AUTOSAR XML (schema 00046)
package /ComponentTypes
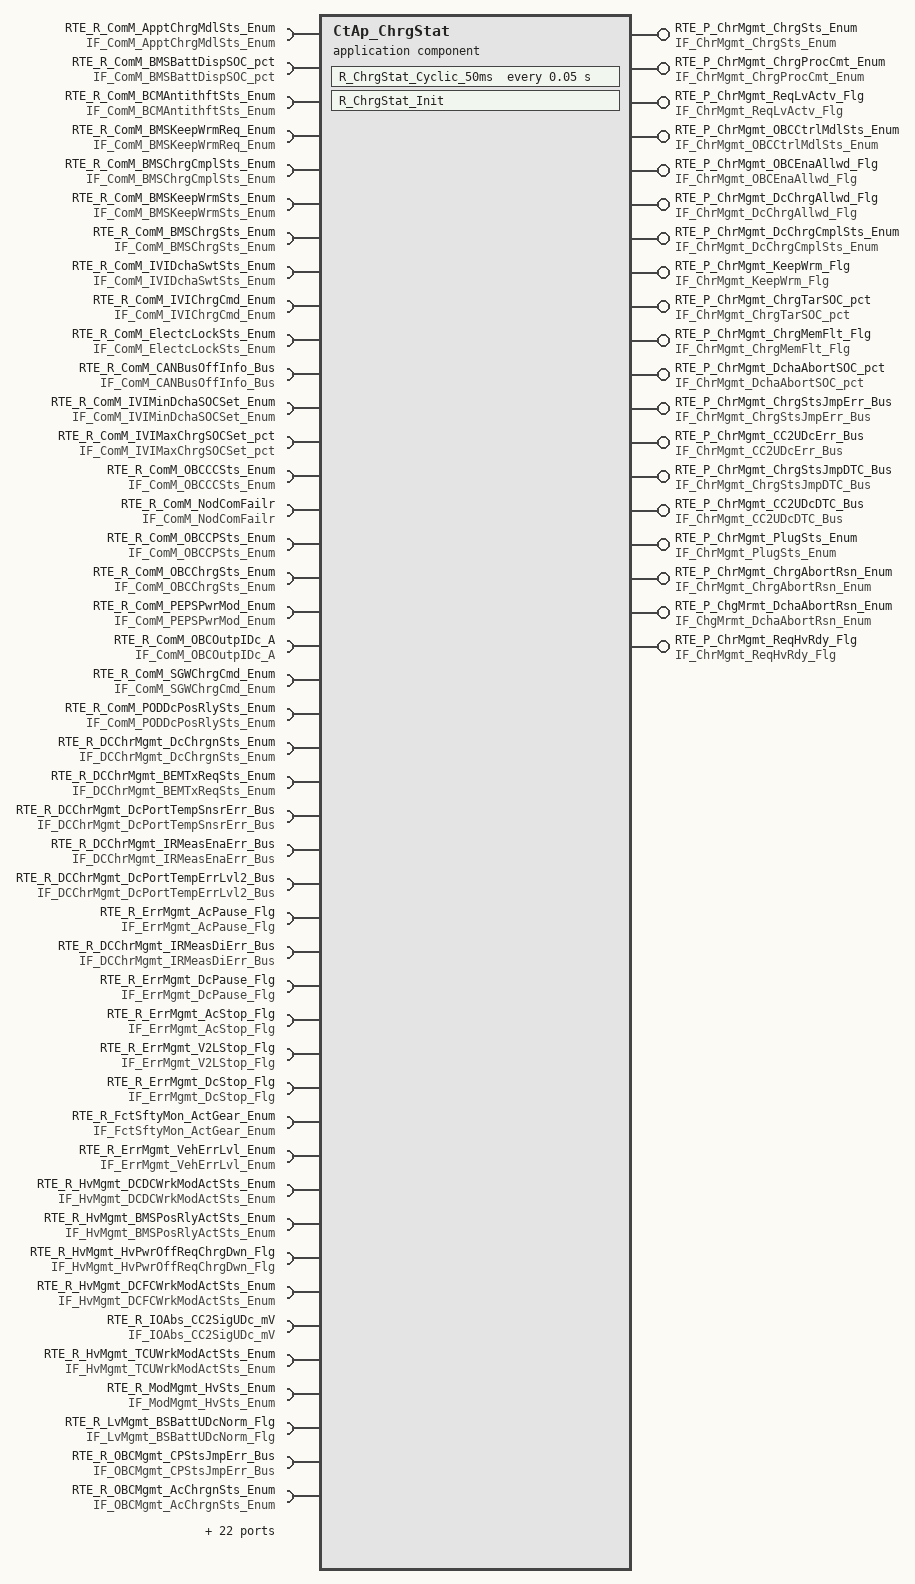
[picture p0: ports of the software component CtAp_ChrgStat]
  application sw component type CtAp_ChrgStat
    18 x provide port:
      RTE_P_ChrMgmt_ChrgSts_Enum: nonqueued-sender-com-spec{data-element=tec_ChrMgmt_ChrgSts_Enum, init-value=0}, provided-interface=IF_ChrMgmt_ChrgSts_Enum
      RTE_P_ChrMgmt_ChrgProcCmt_Enum: nonqueued-sender-com-spec{data-element=tec_ChrMgmt_ChrgProcCmt_Enum, init-value=0}, provided-interface=IF_ChrMgmt_ChrgProcCmt_Enum
      RTE_P_ChrMgmt_ReqLvActv_Flg: nonqueued-sender-com-spec{data-element=tec_ChrMgmt_ReqLvActv_Flg, init-value=0}, provided-interface=IF_ChrMgmt_ReqLvActv_Flg
      RTE_P_ChrMgmt_OBCCtrlMdlSts_Enum: nonqueued-sender-com-spec{data-element=tec_ChrMgmt_OBCCtrlMdlSts_Enum, init-value=0}, provided-interface=IF_ChrMgmt_OBCCtrlMdlSts_Enum
      RTE_P_ChrMgmt_OBCEnaAllwd_Flg: nonqueued-sender-com-spec{data-element=tec_ChrMgmt_OBCEnaAllwd_Flg, init-value=0}, provided-interface=IF_ChrMgmt_OBCEnaAllwd_Flg
      RTE_P_ChrMgmt_DcChrgAllwd_Flg: nonqueued-sender-com-spec{data-element=tec_ChrMgmt_DcChrgAllwd_Flg, init-value=0}, provided-interface=IF_ChrMgmt_DcChrgAllwd_Flg
      RTE_P_ChrMgmt_DcChrgCmplSts_Enum: nonqueued-sender-com-spec{data-element=tec_ChrMgmt_DcChrgCmplSts_Enum, init-value=0}, provided-interface=IF_ChrMgmt_DcChrgCmplSts_Enum
      RTE_P_ChrMgmt_KeepWrm_Flg: nonqueued-sender-com-spec{data-element=tec_ChrMgmt_KeepWrm_Flg, init-value=0}, provided-interface=IF_ChrMgmt_KeepWrm_Flg
      RTE_P_ChrMgmt_ChrgTarSOC_pct: nonqueued-sender-com-spec{data-element=tec_ChrMgmt_ChrgTarSOC_pct, init-value=0}, provided-interface=IF_ChrMgmt_ChrgTarSOC_pct
      RTE_P_ChrMgmt_ChrgMemFlt_Flg: nonqueued-sender-com-spec{data-element=tec_ChrMgmt_ChrgMemFlt_Flg, init-value=0}, provided-interface=IF_ChrMgmt_ChrgMemFlt_Flg
      RTE_P_ChrMgmt_DchaAbortSOC_pct: nonqueued-sender-com-spec{data-element=tec_ChrMgmt_DchaAbortSOC_pct, init-value=0}, provided-interface=IF_ChrMgmt_DchaAbortSOC_pct
      RTE_P_ChrMgmt_ChrgStsJmpErr_Bus: nonqueued-sender-com-spec{data-element=tec_ChrMgmt_ChrgStsJmpErr_Bus, init-value=fields=[ChrMgmt_MonStatChrgStsJmpErr:0, ChrMgmt_MonResChrgStsJmpErr:0, ChrMgmt_ErrStatChrgStsJmpErr:0, ChrMgmt_ErrResChrgStsJmpErr:0]}, provided-interface=IF_ChrMgmt_ChrgStsJmpErr_Bus
      RTE_P_ChrMgmt_CC2UDcErr_Bus: nonqueued-sender-com-spec{data-element=tec_ChrMgmt_CC2UDcErr_Bus, init-value=fields=[ChrMgmt_MonStatCC2UDcErr:0, ChrMgmt_MonResCC2UDcErr:0, ChrMgmt_ErrStatCC2UDcErr:0, ChrMgmt_ErrResCC2UDcErr:0]}, provided-interface=IF_ChrMgmt_CC2UDcErr_Bus
      RTE_P_ChrMgmt_ChrgStsJmpDTC_Bus: nonqueued-sender-com-spec{data-element=tec_ChrMgmt_ChrgStsJmpErrDTC_Bus, init-value=fields=[ChrMgmt_MonStatChrgStsJmpErrDTC:0, ChrMgmt_MonResChrgStsJmpErrDTC:0, ChrMgmt_ErrStatChrgStsJmpErrDTC:0, ChrMgmt_ErrResChrgStsJmpErrDTC:0]}, provided-interface=IF_ChrMgmt_ChrgStsJmpDTC_Bus
      RTE_P_ChrMgmt_CC2UDcDTC_Bus: nonqueued-sender-com-spec{data-element=tec_ChrMgmt_CC2UDcErrDTC_Bus, init-value=fields=[ChrMgmt_MonStatCC2UDcErrDTC:0, ChrMgmt_MonResCC2UDcErrDTC:0, ChrMgmt_ErrStatCC2UDcErrDTC:0, ChrMgmt_ErrResCC2UDcErrDTC:0]}, provided-interface=IF_ChrMgmt_CC2UDcDTC_Bus
      RTE_P_ChrMgmt_PlugSts_Enum: nonqueued-sender-com-spec{data-element=tec_ChrMgmt_PlugSts_Enum, init-value=0}, provided-interface=IF_ChrMgmt_PlugSts_Enum
      RTE_P_ChrMgmt_ChrgAbortRsn_Enum: nonqueued-sender-com-spec{data-element=tec_ChrMgmt_ChrgAbortRsn_Enum, init-value=0}, provided-interface=IF_ChrMgmt_ChrgAbortRsn_Enum
      RTE_P_ChgMrmt_DchaAbortRsn_Enum: nonqueued-sender-com-spec{data-element=tec_ChrMgmt_DchaAbortRsn_Enum, init-value=0}, provided-interface=IF_ChgMrmt_DchaAbortRsn_Enum
    57 x require port:
      RTE_R_ComM_ApptChrgMdlSts_Enum: nonqueued-receiver-com-spec{data-element=tec_ComM_ApptChrgMdlSts_Enum, filter=data-filter-type=ALWAYS, init-value=0}, required-interface=IF_ComM_ApptChrgMdlSts_Enum
      RTE_R_ComM_BMSBattDispSOC_pct: nonqueued-receiver-com-spec{data-element=tec_ComM_BMSBattDispSOC_pct, filter=data-filter-type=ALWAYS, init-value=0}, required-interface=IF_ComM_BMSBattDispSOC_pct
      RTE_R_ComM_BCMAntithftSts_Enum: nonqueued-receiver-com-spec{data-element=tec_ComM_BCMAntithftSts_Enum, filter=data-filter-type=ALWAYS, init-value=0}, required-interface=IF_ComM_BCMAntithftSts_Enum
      RTE_R_ComM_BMSKeepWrmReq_Enum: nonqueued-receiver-com-spec{data-element=tec_ComM_BMSKeepWrmReq_Enum, filter=data-filter-type=ALWAYS, init-value=0}, required-interface=IF_ComM_BMSKeepWrmReq_Enum
      RTE_R_ComM_BMSChrgCmplSts_Enum: nonqueued-receiver-com-spec{data-element=tec_ComM_BMSChrgCmplSts_Enum, filter=data-filter-type=ALWAYS, init-value=0}, required-interface=IF_ComM_BMSChrgCmplSts_Enum
      RTE_R_ComM_BMSKeepWrmSts_Enum: nonqueued-receiver-com-spec{data-element=tec_ComM_BMSKeepWrmSts_Enum, filter=data-filter-type=ALWAYS, init-value=0}, required-interface=IF_ComM_BMSKeepWrmSts_Enum
      RTE_R_ComM_BMSChrgSts_Enum: nonqueued-receiver-com-spec{data-element=tec_ComM_BMSChrgSts_Enum, filter=data-filter-type=ALWAYS, init-value=0}, required-interface=IF_ComM_BMSChrgSts_Enum
      RTE_R_ComM_IVIDchaSwtSts_Enum: nonqueued-receiver-com-spec{data-element=tec_ComM_IVIDchaSwtSts_Enum, filter=data-filter-type=ALWAYS, init-value=0}, required-interface=IF_ComM_IVIDchaSwtSts_Enum
      RTE_R_ComM_IVIChrgCmd_Enum: nonqueued-receiver-com-spec{data-element=tec_ComM_IVIChrgCmd_Enum, filter=data-filter-type=ALWAYS, init-value=0}, required-interface=IF_ComM_IVIChrgCmd_Enum
      RTE_R_ComM_ElectcLockSts_Enum: nonqueued-receiver-com-spec{data-element=tec_ComM_ElectcLockSts_Enum, filter=data-filter-type=ALWAYS, init-value=0}, required-interface=IF_ComM_ElectcLockSts_Enum
      RTE_R_ComM_CANBusOffInfo_Bus: required-interface=IF_ComM_CANBusOffInfo_Bus
        required-com-specs:
          data-element=tec_ComM_EPTCANBusOffInfo_Bus, filter=data-filter-type=ALWAYS, init-value=fields=[ComM_MonStatEPTCANBusOffInfo:0, ComM_MonResEPTCANBusOffInfo:0, ComM_ErrStatEPTCANBusOffInfo:0, ComM_ErrResEPTCANBusOffInfo:0]
          data-element=tec_ComM_CHCANBusOffInfo_Bus, filter=data-filter-type=ALWAYS, init-value=fields=[ComM_MonStatCHCANBusOffInfo:0, ComM_MonResCHCANBusOffInfo:0, ComM_ErrStatCHCANBusOffInfo:0, ComM_ErrResCHCANBusOffInfo:0]
          data-element=tec_ComM_EPTCANBusOffDTCInfo_Bus, filter=data-filter-type=ALWAYS, init-value=fields=[ComM_MonStatEPTCANBusOffDTCInfo:0, ComM_MonResEPTCANBusOffDTCInfo:0, ComM_ErrStatEPTCANBusOffDTCInfo:0, ComM_ErrResEPTCANBusOffDTCInfo:0]
          data-element=tec_ComM_CHCANBusOffDTCInfo_Bus, filter=data-filter-type=ALWAYS, init-value=fields=[ComM_MonStatCHCANBusOffDTCInfo:0, ComM_MonResCHCANBusOffDTCInfo:0, ComM_ErrStatCHCANBusOffDTCInfo:0, ComM_ErrResCHCANBusOffDTCInfo:0]
          data-element=tec_ComM_DCCANBusOffDTCInfo_Bus, init-value=fields=[ComM_MonStatDCCANDTCBusOffInfo:0, ComM_MonResDCCANDTCBusOffInfo:0, ComM_ErrStatDCCANDTCBusOffInfo:0, ComM_ErrResDCCANDTCBusOffInfo:0]
          data-element=tec_ComM_DCCANBusOffInfo_Bus, init-value=fields=[ComM_MonStatDCCANBusOffInfo:0, ComM_MonResDCCANBusOffInfo:0, ComM_ErrStatDCCANBusOffInfo:0, ComM_ErrResDCCANBusOffInfo:0]
      RTE_R_ComM_IVIMinDchaSOCSet_Enum: nonqueued-receiver-com-spec{data-element=tec_ComM_IVIMinDchaSOCSet_Enum, filter=data-filter-type=ALWAYS, init-value=0}, required-interface=IF_ComM_IVIMinDchaSOCSet_Enum
      RTE_R_ComM_IVIMaxChrgSOCSet_pct: nonqueued-receiver-com-spec{data-element=tec_ComM_IVIMaxChrgSOCSet_pct, filter=data-filter-type=ALWAYS, init-value=0}, required-interface=IF_ComM_IVIMaxChrgSOCSet_pct
      RTE_R_ComM_OBCCCSts_Enum: nonqueued-receiver-com-spec{data-element=tec_ComM_OBCCCSts_Enum, filter=data-filter-type=ALWAYS, init-value=0}, required-interface=IF_ComM_OBCCCSts_Enum
      RTE_R_ComM_NodComFailr: required-interface=IF_ComM_NodComFailr
        required-com-specs:
          data-element=tec_ComM_ACUNodComFailr_Flg, filter=data-filter-type=ALWAYS, init-value=0
          data-element=tec_ComM_SGWNodComFailr_Flg, filter=data-filter-type=ALWAYS, init-value=0
          data-element=tec_ComM_CGWNodComFailr_Flg, filter=data-filter-type=ALWAYS, init-value=0
          data-element=tec_ComM_TCUNodComFailr_Flg, filter=data-filter-type=ALWAYS, init-value=0
          data-element=tec_ComM_BCMNodComFailr_Flg, filter=data-filter-type=ALWAYS, init-value=0
          data-element=tec_ComM_PRNDNodComFailr_Flg, filter=data-filter-type=ALWAYS, init-value=0
          data-element=tec_ComM_IVINodComFailr_Flg, filter=data-filter-type=ALWAYS, init-value=0
          data-element=tec_ComM_DCDCNodComFailr_Flg, filter=data-filter-type=ALWAYS, init-value=0
          data-element=tec_ComM_OBCNodComFailr_Flg, filter=data-filter-type=ALWAYS, init-value=0
          data-element=tec_ComM_CHIBSNodComFailr_Flg, filter=data-filter-type=ALWAYS, init-value=0
          data-element=tec_ComM_MCUNodComFailr_Flg, filter=data-filter-type=ALWAYS, init-value=0
          data-element=tec_ComM_EVCOMNodComFailr_Flg, filter=data-filter-type=ALWAYS, init-value=0
          data-element=tec_ComM_EPTIBSNodComFailr_Flg, filter=data-filter-type=ALWAYS, init-value=0
          data-element=tec_ComM_DCMNodComFailr_Flg, filter=data-filter-type=ALWAYS, init-value=0
          data-element=tec_ComM_BMSNodComFailr_Flg, filter=data-filter-type=ALWAYS, init-value=0
          data-element=tec_ComM_APTCNodComFailr_Flg, filter=data-filter-type=ALWAYS, init-value=0
          data-element=tec_ComM_ADCUNodComFailr_Flg, filter=data-filter-type=ALWAYS, init-value=0
          data-element=tec_ComM_DCMRRNodComFailr_Flg, filter=data-filter-type=ALWAYS, init-value=0
          data-element=tec_ComM_DCMRLNodComFailr_Flg, filter=data-filter-type=ALWAYS, init-value=0
          data-element=tec_ComM_DCMFRNodComFailr_Flg, filter=data-filter-type=ALWAYS, init-value=0
          data-element=tec_ComM_DCMFLNodComFailr_Flg, filter=data-filter-type=ALWAYS, init-value=0
          data-element=tec_ComM_SGWCHNodComFailr_Flg, init-value=0
      RTE_R_ComM_OBCCPSts_Enum: nonqueued-receiver-com-spec{data-element=tec_ComM_OBCCPSts_Enum, filter=data-filter-type=ALWAYS, init-value=0}, required-interface=IF_ComM_OBCCPSts_Enum
      RTE_R_ComM_OBCChrgSts_Enum: nonqueued-receiver-com-spec{data-element=tec_ComM_OBCChrgSts_Enum, filter=data-filter-type=ALWAYS, init-value=0}, required-interface=IF_ComM_OBCChrgSts_Enum
      RTE_R_ComM_PEPSPwrMod_Enum: nonqueued-receiver-com-spec{data-element=tec_ComM_PEPSPwrMod_Enum, filter=data-filter-type=ALWAYS, init-value=0}, required-interface=IF_ComM_PEPSPwrMod_Enum
      RTE_R_ComM_OBCOutpIDc_A: nonqueued-receiver-com-spec{data-element=tec_ComM_OBCOutpIDc_A, filter=data-filter-type=ALWAYS, init-value=0}, required-interface=IF_ComM_OBCOutpIDc_A
      RTE_R_ComM_SGWChrgCmd_Enum: nonqueued-receiver-com-spec{data-element=tec_ComM_SGWChrgCmd_Enum, filter=data-filter-type=ALWAYS, init-value=0}, required-interface=IF_ComM_SGWChrgCmd_Enum
      RTE_R_ComM_PODDcPosRlySts_Enum: nonqueued-receiver-com-spec{data-element=tec_ComM_PODDcPosRlySts_Enum, filter=data-filter-type=ALWAYS, init-value=0}, required-interface=IF_ComM_PODDcPosRlySts_Enum
      RTE_R_DCChrMgmt_DcChrgnSts_Enum: nonqueued-receiver-com-spec{data-element=tec_DCChrMgmt_DcChrgnSts_Enum, filter=data-filter-type=ALWAYS, init-value=0}, required-interface=IF_DCChrMgmt_DcChrgnSts_Enum
      RTE_R_DCChrMgmt_BEMTxReqSts_Enum: nonqueued-receiver-com-spec{data-element=tec_DCChrMgmt_BEMTxReqSts_Enum, filter=data-filter-type=ALWAYS, init-value=0}, required-interface=IF_DCChrMgmt_BEMTxReqSts_Enum
      RTE_R_DCChrMgmt_DcPortTempSnsrErr_Bus: nonqueued-receiver-com-spec{data-element=tec_DCChrMgmt_DcPortTempSnsrErr_Bus, filter=data-filter-type=ALWAYS, init-value=fields=[DCChrMgmt_MonStatDcPortTempSnsrErr:0, DCChrMgmt_MonResDcPortTempSnsrErr:0, DCChrMgmt_ErrStatDcPortTempSnsrErr:0, DCChrMgmt_ErrResDcPortTempSnsrErr:0]}, required-interface=IF_DCChrMgmt_DcPortTempSnsrErr_Bus
      RTE_R_DCChrMgmt_IRMeasEnaErr_Bus: nonqueued-receiver-com-spec{data-element=tec_DCChrMgmt_IRMeasEnaErr_Bus, filter=data-filter-type=ALWAYS, init-value=fields=[DCChrMgmt_MonStatIRMeasEnaErr:0, DCChrMgmt_MonResIRMeasEnaErr:0, DCChrMgmt_ErrStatIRMeasEnaErr:0, DCChrMgmt_ErrResIRMeasEnaErr:0]}, required-interface=IF_DCChrMgmt_IRMeasEnaErr_Bus
      RTE_R_DCChrMgmt_DcPortTempErrLvl2_Bus: nonqueued-receiver-com-spec{data-element=tec_DCChrMgmt_DcPortTempErrLvl2_Bus, filter=data-filter-type=ALWAYS, init-value=fields=[DCChrMgmt_MonStatDcPortTempErrLvl2:0, DCChrMgmt_MonResDcPortTempErrLvl2:0, DCChrMgmt_ErrStatDcPortTempErrLvl2:0, DCChrMgmt_ErrResDcPortTempErrLvl2:0]}, required-interface=IF_DCChrMgmt_DcPortTempErrLvl2_Bus
      RTE_R_ErrMgmt_AcPause_Flg: nonqueued-receiver-com-spec{data-element=tec_ErrMgmt_AcPause_Flg, filter=data-filter-type=ALWAYS, init-value=0}, required-interface=IF_ErrMgmt_AcPause_Flg
      RTE_R_DCChrMgmt_IRMeasDiErr_Bus: nonqueued-receiver-com-spec{data-element=tec_DCChrMgmt_IRMeasDiErr_Bus, filter=data-filter-type=ALWAYS, init-value=fields=[DCChrMgmt_MonStatIRMeasDiErr:0, DCChrMgmt_MonResIRMeasDiErr:0, DCChrMgmt_ErrStatIRMeasDiErr:0, DCChrMgmt_ErrResIRMeasDiErr:0]}, required-interface=IF_DCChrMgmt_IRMeasDiErr_Bus
      RTE_R_ErrMgmt_DcPause_Flg: nonqueued-receiver-com-spec{data-element=tec_ErrMgmt_DcPause_Flg, filter=data-filter-type=ALWAYS, init-value=0}, required-interface=IF_ErrMgmt_DcPause_Flg
      RTE_R_ErrMgmt_AcStop_Flg: nonqueued-receiver-com-spec{data-element=tec_ErrMgmt_AcStop_Flg, filter=data-filter-type=ALWAYS, init-value=0}, required-interface=IF_ErrMgmt_AcStop_Flg
      RTE_R_ErrMgmt_V2LStop_Flg: nonqueued-receiver-com-spec{data-element=tec_ErrMgmt_V2LStop_Flg, filter=data-filter-type=ALWAYS, init-value=0}, required-interface=IF_ErrMgmt_V2LStop_Flg
      RTE_R_ErrMgmt_DcStop_Flg: nonqueued-receiver-com-spec{data-element=tec_ErrMgmt_DcStop_Flg, filter=data-filter-type=ALWAYS, init-value=0}, required-interface=IF_ErrMgmt_DcStop_Flg
      RTE_R_FctSftyMon_ActGear_Enum: nonqueued-receiver-com-spec{data-element=tec_FctSftyMon_ActGear_Enum, filter=data-filter-type=ALWAYS, init-value=0}, required-interface=IF_FctSftyMon_ActGear_Enum
      RTE_R_ErrMgmt_VehErrLvl_Enum: nonqueued-receiver-com-spec{data-element=tec_ErrMgmt_VehErrLvl_Enum, filter=data-filter-type=ALWAYS, init-value=0}, required-interface=IF_ErrMgmt_VehErrLvl_Enum
      RTE_R_HvMgmt_DCDCWrkModActSts_Enum: nonqueued-receiver-com-spec{data-element=tec_HvMgmt_DCDCWrkModActSts_Enum, filter=data-filter-type=ALWAYS, init-value=0}, required-interface=IF_HvMgmt_DCDCWrkModActSts_Enum
      RTE_R_HvMgmt_BMSPosRlyActSts_Enum: nonqueued-receiver-com-spec{data-element=tec_HvMgmt_BMSPosRlyActSts_Enum, filter=data-filter-type=ALWAYS, init-value=0}, required-interface=IF_HvMgmt_BMSPosRlyActSts_Enum
      RTE_R_HvMgmt_HvPwrOffReqChrgDwn_Flg: nonqueued-receiver-com-spec{data-element=tec_HvMgmt_HvPwrOffReqChrgDwn_Flg, filter=data-filter-type=ALWAYS, init-value=0}, required-interface=IF_HvMgmt_HvPwrOffReqChrgDwn_Flg
      RTE_R_HvMgmt_DCFCWrkModActSts_Enum: nonqueued-receiver-com-spec{data-element=tec_HvMgmt_DCFCWrkModActSts_Enum, filter=data-filter-type=ALWAYS, init-value=0}, required-interface=IF_HvMgmt_DCFCWrkModActSts_Enum
      RTE_R_IOAbs_CC2SigUDc_mV: nonqueued-receiver-com-spec{data-element=tec_IOAbs_CC2SigUDc_mV, filter=data-filter-type=ALWAYS, init-value=0}, required-interface=IF_IOAbs_CC2SigUDc_mV
      RTE_R_HvMgmt_TCUWrkModActSts_Enum: nonqueued-receiver-com-spec{data-element=tec_HvMgmt_TCUWrkModActSts_Enum, filter=data-filter-type=ALWAYS, init-value=0}, required-interface=IF_HvMgmt_TCUWrkModActSts_Enum
      RTE_R_ModMgmt_HvSts_Enum: nonqueued-receiver-com-spec{data-element=tec_ModMgmt_HvSts_Enum, filter=data-filter-type=ALWAYS, init-value=0}, required-interface=IF_ModMgmt_HvSts_Enum
      RTE_R_LvMgmt_BSBattUDcNorm_Flg: nonqueued-receiver-com-spec{data-element=tec_LvMgmt_BSBattUDcNorm_Flg, filter=data-filter-type=ALWAYS, init-value=0}, required-interface=IF_LvMgmt_BSBattUDcNorm_Flg
      RTE_R_OBCMgmt_CPStsJmpErr_Bus: nonqueued-receiver-com-spec{data-element=tec_OBCMgmt_CPStsJmpErr_Bus, filter=data-filter-type=ALWAYS, init-value=fields=[OBCMgmt_MonStatCPStsJmpErr:0, OBCMgmt_MonResCPStsJmpErr:0, OBCMgmt_ErrStatCPStsJmpErr:0, OBCMgmt_ErrResCPStsJmpErr:0]}, required-interface=IF_OBCMgmt_CPStsJmpErr_Bus
      RTE_R_OBCMgmt_AcChrgnSts_Enum: nonqueued-receiver-com-spec{data-element=tec_OBCMgmt_AcChrgnSts_Enum, filter=data-filter-type=ALWAYS, init-value=0}, required-interface=IF_OBCMgmt_AcChrgnSts_Enum
      RTE_R_OBCMgmt_OBCDchaStsErr_Bus: nonqueued-receiver-com-spec{data-element=tec_OBCMgmt_OBCDchaStsErr_Bus, filter=data-filter-type=ALWAYS, init-value=fields=[OBCMgmt_MonStatOBCDchaStsErr:0, OBCMgmt_MonResOBCDchaStsErr:0, OBCMgmt_ErrStatOBCDchaStsErr:0, OBCMgmt_ErrResOBCDchaStsErr:0]}, required-interface=IF_OBCMgmt_OBCDchaStsErr_Bus
      RTE_R_OBCMgmt_OBCChrgStsErr_Bus: nonqueued-receiver-com-spec{data-element=tec_OBCMgmt_OBCChrgStsErr_Bus, filter=data-filter-type=ALWAYS, init-value=fields=[OBCMgmt_MonStatOBCChrgStsErr:0, OBCMgmt_MonResOBCChrgStsErr:0, OBCMgmt_ErrStatOBCChrgStsErr:0, OBCMgmt_ErrResOBCChrgStsErr:0]}, required-interface=IF_OBCMgmt_OBCChrgStsErr_Bus
      RTE_R_OBCMgmt_OBCInpUDcLoErr_Bus: nonqueued-receiver-com-spec{data-element=tec_OBCMgmt_OBCInpUDcLoErr_Bus, filter=data-filter-type=ALWAYS, init-value=fields=[OBCMgmt_MonStatOBCInpUDcLoErr:0, OBCMgmt_MonResOBCInpUDcLoErr:0, OBCMgmt_ErrStatOBCInpUDcLoErr:0, OBCMgmt_ErrResOBCInpUDcLoErr:0]}, required-interface=IF_OBCMgmt_OBCInpUDcLoErr_Bus
      RTE_R_OBCMgmt_S2SwtClsErr_Bus: nonqueued-receiver-com-spec{data-element=tec_OBCMgmt_S2SwtClsErr_Bus, filter=data-filter-type=ALWAYS, init-value=fields=[OBCMgmt_MonStatS2SwtClsErr:0, OBCMgmt_MonResS2SwtClsErr:0, OBCMgmt_ErrStatS2SwtClsErr:0, OBCMgmt_ErrResS2SwtClsErr:0]}, required-interface=IF_OBCMgmt_S2SwtClsErr_Bus
      RTE_R_VehMot_VehStdl_Flg: nonqueued-receiver-com-spec{data-element=tec_VehMot_VehStdl_Flg, filter=data-filter-type=ALWAYS, init-value=0}, required-interface=IF_VehMot_VehStdl_Flg
      RTE_R_OBCMgmt_OBCDiErr_Bus: nonqueued-receiver-com-spec{data-element=tec_OBCMgmt_OBCDiErr_Bus, filter=data-filter-type=ALWAYS, init-value=fields=[OBCMgmt_MonStatOBCDiErr:0, OBCMgmt_MonResOBCDiErr:0, OBCMgmt_ErrStatOBCDiErr:0, OBCMgmt_ErrResOBCDiErr:0]}, required-interface=IF_OBCMgmt_OBCDiErr_Bus
      RTE_R_OBCMgmt_OBCPreheatStsErr_Bus: nonqueued-receiver-com-spec{data-element=tec_OBCMgmt_OBCPreheatStsErr_Bus, filter=data-filter-type=ALWAYS, init-value=fields=[OBCMgmt_MonStatOBCPreheatStsErr:0, OBCMgmt_MonResOBCPreheatStsErr:0, OBCMgmt_ErrStatOBCPreheatStsErr:0, OBCMgmt_ErrResOBCPreheatStsErr:0]}, required-interface=IF_OBCMgmt_OBCPreheatStsErr_Bus
      RTE_R_ChrMgmt_AcPreheatUDcCtrlErr_Bus: nonqueued-receiver-com-spec{data-element=tec_ChrMgmt_AcPreheatUDcCtrlErr_Bus, filter=data-filter-type=ALWAYS, init-value=fields=[ChrMgmt_MonStatAcPreheatUDcCtrlErr:0, ChrMgmt_MonResAcPreheatUDcCtrlErr:0, ChrMgmt_ErrStatAcPreheatUDcCtrlErr:0, ChrMgmt_ErrResAcPreheatUDcCtrlErr:0]}, required-interface=IF_ChrMgmt_AcPreheatUDcCtrlErr_Bus
      RTE_R_ChrMgmt_DcPreheatUDcCtrlErr_Bus: nonqueued-receiver-com-spec{data-element=tec_ChrMgmt_DcPreheatUDcCtrlErr_Bus, filter=data-filter-type=ALWAYS, init-value=fields=[ChrMgmt_MonStatDcPreheatUDcCtrlErr:0, ChrMgmt_MonResDcPreheatUDcCtrlErr:0, ChrMgmt_ErrStatDcPreheatUDcCtrlErr:0, ChrMgmt_ErrResDcPreheatUDcCtrlErr:0]}, required-interface=IF_ChrMgmt_DcPreheatUDcCtrlErr_Bus
      RTE_R_ChrMgmt_PreheatIRChkErr_Bus: nonqueued-receiver-com-spec{data-element=tec_ChrMgmt_PreheatIRChkErr_Bus, filter=data-filter-type=ALWAYS, init-value=fields=[ChrMgmt_MonStatPreheatIRChkErr:0, ChrMgmt_MonResPreheatIRChkErr:0, ChrMgmt_ErrStatPreheatIRChkErr:0, ChrMgmt_ErrResPreheatIRChkErr:0]}, required-interface=IF_ChrMgmt_PreheatIRChkErr_Bus
      RTE_R_ChrMgmt_KeepWrmTim_min: nonqueued-receiver-com-spec{data-element=tec_ChrMgmt_KeepWrmTim_min, filter=data-filter-type=ALWAYS, init-value=0}, required-interface=IF_ChrMgmt_KeepWrmTim_min
      RTE_R_ChrMgmt_PreheatSts_Enum: nonqueued-receiver-com-spec{data-element=tec_ChrMgmt_PreheatSts_Enum, filter=data-filter-type=ALWAYS, init-value=0}, required-interface=IF_ChrMgmt_PreheatSts_Enum
      RTE_R_ChrMgmt_VCUCalcdPODIDc_A: nonqueued-receiver-com-spec{data-element=tec_ChrMgmt_VCUCalcdPODIDc_A, filter=data-filter-type=ALWAYS, init-value=0}, required-interface=IF_ChrMgmt_VCUCalcdPODIDc_A
    provide port RTE_P_ChrMgmt_ReqHvRdy_Flg: nonqueued-sender-com-spec{data-element=tec_ChrMgmt_ReqHvRdy_Flg, init-value=0}, provided-interface=IF_ChrMgmt_ReqHvRdy_Flg
    provide/require port RTE_RP_ChrgStatInfo:
      nv-provide-com-spec{ram-block-init-value=fields=[ChrMgmt_ChrgTarSOC_pct:0, ChrMgmt_ChrgMemFlt_Flg:0, ChrMgmt_DchaAbortSOC_pct:0, ChrMgmt_FillAddress:0], rom-block-init-value=fields=[ChrMgmt_ChrgTarSOC_pct:0, ChrMgmt_ChrgMemFlt_Flg:0, ChrMgmt_DchaAbortSOC_pct:0, ChrMgmt_FillAddress:0], variable=tec_ChrgStatInfo}
      nv-require-com-spec{init-value=fields=[ChrMgmt_ChrgTarSOC_pct:0, ChrMgmt_ChrgMemFlt_Flg:0, ChrMgmt_DchaAbortSOC_pct:0, ChrMgmt_FillAddress:0], variable=tec_ChrgStatInfo}
      provided-required-interface=IF_ChrgStatInfo
    9 x require port:
      UDS_PwrCutRequest: nonqueued-receiver-com-spec{data-element=PwrCutRequest, filter=data-filter-type=ALWAYS, init-value=0}, required-interface=UDS_PwrCutRequest
      RTE_R_DiagApp_DisableDCMReqInfo: nonqueued-receiver-com-spec{data-element=tec_DiagApp_DisableDCMReqInfo, filter=data-filter-type=ALWAYS, init-value=0}, required-interface=IF_DiagApp_DisableDCMReqInfo
      RTE_R_ComM_OBCCPPwmDuty_pct: nonqueued-receiver-com-spec{data-element=tec_ComM_OBCCPPwmDuty_pct, filter=data-filter-type=ALWAYS, init-value=0}, required-interface=IF_ComM_OBCCPPwmDuty_pct
      RTE_R_HvMgmt_BMSNegRlyActSts_Enum: nonqueued-receiver-com-spec{data-element=tec_HvMgmt_BMSNegRlyActSts_Enum, filter=data-filter-type=ALWAYS, init-value=0}, required-interface=IF_HvMgmt_BMSNegRlyActSts_Enum
      RTE_R_ComM_RxSts_Flg: required-interface=IF_ComM_RxSts_Flg
        required-com-specs:
          data-element=tec_ComM_RxCROSts_Flg, filter=data-filter-type=ALWAYS, init-value=0
          data-element=tec_ComM_RxCEMSts_Flg, filter=data-filter-type=ALWAYS, init-value=0
          data-element=tec_ComM_RxCHMSts_Flg, filter=data-filter-type=ALWAYS, init-value=0
          data-element=tec_ComM_RxCSTSts_Flg, filter=data-filter-type=ALWAYS, init-value=0
          data-element=tec_ComM_RxCSDSts_Flg, filter=data-filter-type=ALWAYS, init-value=0
          data-element=tec_ComM_RxCCSSts_Flg, filter=data-filter-type=ALWAYS, init-value=0
          data-element=tec_ComM_RxCMLSts_Flg, filter=data-filter-type=ALWAYS, init-value=0
          data-element=tec_ComM_RxCRMSts_Flg, filter=data-filter-type=ALWAYS, init-value=0
      RTE_R_OBCMgmt_OBCEnaCmd_Enum: nonqueued-receiver-com-spec{data-element=tec_OBCMgmt_OBCEnaCmd_Enum, filter=data-filter-type=ALWAYS, init-value=0}, required-interface=IF_OBCMgmt_OBCEnaCmd_Enum
      RTE_R_ComM_SGWDchaSwtSts: nonqueued-receiver-com-spec{data-element=tec_ComM_SGWDchaSwtSts, filter=data-filter-type=ALWAYS, init-value=0}, required-interface=IF_ComM_SGWDchaSwtSts
      RTE_R_DCChrMgmt_BSTTxReqSts: nonqueued-receiver-com-spec{data-element=tec_DCChrMgmt_BSTTxReqSts, filter=data-filter-type=ALWAYS, init-value=0}, required-interface=IF_DCChrMgmt_BSTTxReqSts
      RTE_R_VehMot_VehSpdVld_Flg: nonqueued-receiver-com-spec{data-element=tec_VehMot_VehSpdVld_Flg, filter=data-filter-type=ALWAYS, init-value=0}, required-interface=IF_VehMot_VehSpdVld_Flg
    behavior CtAp_ChrgStat_InternalBehavior
      timing event TMT_R_ChrgStat_Cyclic_50ms: start-on-event=R_ChrgStat_Cyclic_50ms, period=0.05
      init event CtAp_ChrgStat_InitEvent: start-on-event=R_ChrgStat_Init
      runnable R_ChrgStat_Cyclic_50ms
        data-receive-point-by-arguments:
          68 x access:
            REC_RTE_R_ChrMgmt_AcPreheatUDcCtrlErr_Bus_tec_ChrMgmt_AcPreheatUDcCtrlErr_Bus: accessed-variable=RTE_R_ChrMgmt_AcPreheatUDcCtrlErr_Bus.tec_ChrMgmt_AcPreheatUDcCtrlErr_Bus
            REC_RTE_R_ChrMgmt_DcPreheatUDcCtrlErr_Bus_tec_ChrMgmt_DcPreheatUDcCtrlErr_Bus: accessed-variable=RTE_R_ChrMgmt_DcPreheatUDcCtrlErr_Bus.tec_ChrMgmt_DcPreheatUDcCtrlErr_Bus
            REC_RTE_R_ChrMgmt_KeepWrmTim_min_tec_ChrMgmt_KeepWrmTim_min: accessed-variable=RTE_R_ChrMgmt_KeepWrmTim_min.tec_ChrMgmt_KeepWrmTim_min
            REC_RTE_R_ChrMgmt_PreheatIRChkErr_Bus_tec_ChrMgmt_PreheatIRChkErr_Bus: accessed-variable=RTE_R_ChrMgmt_PreheatIRChkErr_Bus.tec_ChrMgmt_PreheatIRChkErr_Bus
            REC_RTE_R_ChrMgmt_PreheatSts_Enum_tec_ChrMgmt_PreheatSts_Enum: accessed-variable=RTE_R_ChrMgmt_PreheatSts_Enum.tec_ChrMgmt_PreheatSts_Enum
            REC_RTE_R_ChrMgmt_VCUCalcdPODIDc_A_tec_ChrMgmt_VCUCalcdPODIDc_A: accessed-variable=RTE_R_ChrMgmt_VCUCalcdPODIDc_A.tec_ChrMgmt_VCUCalcdPODIDc_A
            REC_RTE_R_ComM_ApptChrgMdlSts_Enum_tec_ComM_ApptChrgMdlSts_Enum: accessed-variable=RTE_R_ComM_ApptChrgMdlSts_Enum.tec_ComM_ApptChrgMdlSts_Enum
            REC_RTE_R_ComM_BCMAntithftSts_Enum_tec_ComM_BCMAntithftSts_Enum: accessed-variable=RTE_R_ComM_BCMAntithftSts_Enum.tec_ComM_BCMAntithftSts_Enum
            REC_RTE_R_ComM_BMSBattDispSOC_pct_tec_ComM_BMSBattDispSOC_pct: accessed-variable=RTE_R_ComM_BMSBattDispSOC_pct.tec_ComM_BMSBattDispSOC_pct
            REC_RTE_R_ComM_BMSChrgCmplSts_Enum_tec_ComM_BMSChrgCmplSts_Enum: accessed-variable=RTE_R_ComM_BMSChrgCmplSts_Enum.tec_ComM_BMSChrgCmplSts_Enum
            REC_RTE_R_ComM_BMSChrgSts_Enum_tec_ComM_BMSChrgSts_Enum: accessed-variable=RTE_R_ComM_BMSChrgSts_Enum.tec_ComM_BMSChrgSts_Enum
            REC_RTE_R_ComM_BMSKeepWrmReq_Enum_tec_ComM_BMSKeepWrmReq_Enum: accessed-variable=RTE_R_ComM_BMSKeepWrmReq_Enum.tec_ComM_BMSKeepWrmReq_Enum
            REC_RTE_R_ComM_BMSKeepWrmSts_Enum_tec_ComM_BMSKeepWrmSts_Enum: accessed-variable=RTE_R_ComM_BMSKeepWrmSts_Enum.tec_ComM_BMSKeepWrmSts_Enum
            REC_RTE_R_ComM_CANBusOffInfo_Bus_tec_ComM_EPTCANBusOffInfo_Bus: accessed-variable=RTE_R_ComM_CANBusOffInfo_Bus.tec_ComM_EPTCANBusOffInfo_Bus
            REC_RTE_R_ComM_ElectcLockSts_Enum_tec_ComM_ElectcLockSts_Enum: accessed-variable=RTE_R_ComM_ElectcLockSts_Enum.tec_ComM_ElectcLockSts_Enum
            REC_RTE_R_ComM_IVIChrgCmd_Enum_tec_ComM_IVIChrgCmd_Enum: accessed-variable=RTE_R_ComM_IVIChrgCmd_Enum.tec_ComM_IVIChrgCmd_Enum
            REC_RTE_R_ComM_IVIDchaSwtSts_Enum_tec_ComM_IVIDchaSwtSts_Enum: accessed-variable=RTE_R_ComM_IVIDchaSwtSts_Enum.tec_ComM_IVIDchaSwtSts_Enum
            REC_RTE_R_ComM_IVIMaxChrgSOCSet_pct_tec_ComM_IVIMaxChrgSOCSet_pct: accessed-variable=RTE_R_ComM_IVIMaxChrgSOCSet_pct.tec_ComM_IVIMaxChrgSOCSet_pct
            REC_RTE_R_ComM_IVIMinDchaSOCSet_Enum_tec_ComM_IVIMinDchaSOCSet_Enum: accessed-variable=RTE_R_ComM_IVIMinDchaSOCSet_Enum.tec_ComM_IVIMinDchaSOCSet_Enum
            REC_RTE_R_ComM_NodComFailr_tec_ComM_BMSNodComFailr_Flg: accessed-variable=RTE_R_ComM_NodComFailr.tec_ComM_BMSNodComFailr_Flg
            REC_RTE_R_ComM_NodComFailr_tec_ComM_OBCNodComFailr_Flg: accessed-variable=RTE_R_ComM_NodComFailr.tec_ComM_OBCNodComFailr_Flg
            REC_RTE_R_ComM_OBCCCSts_Enum_tec_ComM_OBCCCSts_Enum: accessed-variable=RTE_R_ComM_OBCCCSts_Enum.tec_ComM_OBCCCSts_Enum
            REC_RTE_R_ComM_OBCCPSts_Enum_tec_ComM_OBCCPSts_Enum: accessed-variable=RTE_R_ComM_OBCCPSts_Enum.tec_ComM_OBCCPSts_Enum
            REC_RTE_R_ComM_OBCChrgSts_Enum_tec_ComM_OBCChrgSts_Enum: accessed-variable=RTE_R_ComM_OBCChrgSts_Enum.tec_ComM_OBCChrgSts_Enum
            REC_RTE_R_ComM_OBCOutpIDc_A_tec_ComM_OBCOutpIDc_A: accessed-variable=RTE_R_ComM_OBCOutpIDc_A.tec_ComM_OBCOutpIDc_A
            REC_RTE_R_ComM_PEPSPwrMod_Enum_tec_ComM_PEPSPwrMod_Enum: accessed-variable=RTE_R_ComM_PEPSPwrMod_Enum.tec_ComM_PEPSPwrMod_Enum
            REC_RTE_R_ComM_PODDcPosRlySts_Enum_tec_ComM_PODDcPosRlySts_Enum: accessed-variable=RTE_R_ComM_PODDcPosRlySts_Enum.tec_ComM_PODDcPosRlySts_Enum
            REC_RTE_R_ComM_SGWChrgCmd_Enum_tec_ComM_SGWChrgCmd_Enum: accessed-variable=RTE_R_ComM_SGWChrgCmd_Enum.tec_ComM_SGWChrgCmd_Enum
            REC_RTE_R_DCChrMgmt_BEMTxReqSts_Enum_tec_DCChrMgmt_BEMTxReqSts_Enum: accessed-variable=RTE_R_DCChrMgmt_BEMTxReqSts_Enum.tec_DCChrMgmt_BEMTxReqSts_Enum
            REC_RTE_R_DCChrMgmt_DcChrgnSts_Enum_tec_DCChrMgmt_DcChrgnSts_Enum: accessed-variable=RTE_R_DCChrMgmt_DcChrgnSts_Enum.tec_DCChrMgmt_DcChrgnSts_Enum
            REC_RTE_R_DCChrMgmt_DcPortTempErrLvl2_Bus_tec_DCChrMgmt_DcPortTempErrLvl2_Bus: accessed-variable=RTE_R_DCChrMgmt_DcPortTempErrLvl2_Bus.tec_DCChrMgmt_DcPortTempErrLvl2_Bus
            REC_RTE_R_DCChrMgmt_DcPortTempSnsrErr_Bus_tec_DCChrMgmt_DcPortTempSnsrErr_Bus: accessed-variable=RTE_R_DCChrMgmt_DcPortTempSnsrErr_Bus.tec_DCChrMgmt_DcPortTempSnsrErr_Bus
            REC_RTE_R_DCChrMgmt_IRMeasDiErr_Bus_tec_DCChrMgmt_IRMeasDiErr_Bus: accessed-variable=RTE_R_DCChrMgmt_IRMeasDiErr_Bus.tec_DCChrMgmt_IRMeasDiErr_Bus
            REC_RTE_R_DCChrMgmt_IRMeasEnaErr_Bus_tec_DCChrMgmt_IRMeasEnaErr_Bus: accessed-variable=RTE_R_DCChrMgmt_IRMeasEnaErr_Bus.tec_DCChrMgmt_IRMeasEnaErr_Bus
            REC_RTE_R_ErrMgmt_AcPause_Flg_tec_ErrMgmt_AcPause_Flg: accessed-variable=RTE_R_ErrMgmt_AcPause_Flg.tec_ErrMgmt_AcPause_Flg
            REC_RTE_R_ErrMgmt_AcStop_Flg_tec_ErrMgmt_AcStop_Flg: accessed-variable=RTE_R_ErrMgmt_AcStop_Flg.tec_ErrMgmt_AcStop_Flg
            REC_RTE_R_ErrMgmt_DcPause_Flg_tec_ErrMgmt_DcPause_Flg: accessed-variable=RTE_R_ErrMgmt_DcPause_Flg.tec_ErrMgmt_DcPause_Flg
            REC_RTE_R_ErrMgmt_DcStop_Flg_tec_ErrMgmt_DcStop_Flg: accessed-variable=RTE_R_ErrMgmt_DcStop_Flg.tec_ErrMgmt_DcStop_Flg
            REC_RTE_R_ErrMgmt_V2LStop_Flg_tec_ErrMgmt_V2LStop_Flg: accessed-variable=RTE_R_ErrMgmt_V2LStop_Flg.tec_ErrMgmt_V2LStop_Flg
            REC_RTE_R_ErrMgmt_VehErrLvl_Enum_tec_ErrMgmt_VehErrLvl_Enum: accessed-variable=RTE_R_ErrMgmt_VehErrLvl_Enum.tec_ErrMgmt_VehErrLvl_Enum
            REC_RTE_R_FctSftyMon_ActGear_Enum_tec_FctSftyMon_ActGear_Enum: accessed-variable=RTE_R_FctSftyMon_ActGear_Enum.tec_FctSftyMon_ActGear_Enum
            REC_RTE_R_HvMgmt_BMSPosRlyActSts_Enum_tec_HvMgmt_BMSPosRlyActSts_Enum: accessed-variable=RTE_R_HvMgmt_BMSPosRlyActSts_Enum.tec_HvMgmt_BMSPosRlyActSts_Enum
            REC_RTE_R_HvMgmt_DCDCWrkModActSts_Enum_tec_HvMgmt_DCDCWrkModActSts_Enum: accessed-variable=RTE_R_HvMgmt_DCDCWrkModActSts_Enum.tec_HvMgmt_DCDCWrkModActSts_Enum
            REC_RTE_R_HvMgmt_DCFCWrkModActSts_Enum_tec_HvMgmt_DCFCWrkModActSts_Enum: accessed-variable=RTE_R_HvMgmt_DCFCWrkModActSts_Enum.tec_HvMgmt_DCFCWrkModActSts_Enum
            REC_RTE_R_HvMgmt_HvPwrOffReqChrgDwn_Flg_tec_HvMgmt_HvPwrOffReqChrgDwn_Flg: accessed-variable=RTE_R_HvMgmt_HvPwrOffReqChrgDwn_Flg.tec_HvMgmt_HvPwrOffReqChrgDwn_Flg
            REC_RTE_R_HvMgmt_TCUWrkModActSts_Enum_tec_HvMgmt_TCUWrkModActSts_Enum: accessed-variable=RTE_R_HvMgmt_TCUWrkModActSts_Enum.tec_HvMgmt_TCUWrkModActSts_Enum
            REC_RTE_R_IOAbs_CC2SigUDc_mV_tec_IOAbs_CC2SigUDc_mV: accessed-variable=RTE_R_IOAbs_CC2SigUDc_mV.tec_IOAbs_CC2SigUDc_mV
            REC_RTE_R_LvMgmt_BSBattUDcNorm_Flg_tec_LvMgmt_BSBattUDcNorm_Flg: accessed-variable=RTE_R_LvMgmt_BSBattUDcNorm_Flg.tec_LvMgmt_BSBattUDcNorm_Flg
            REC_RTE_R_ModMgmt_HvSts_Enum_tec_ModMgmt_HvSts_Enum: accessed-variable=RTE_R_ModMgmt_HvSts_Enum.tec_ModMgmt_HvSts_Enum
            REC_RTE_R_OBCMgmt_AcChrgnSts_Enum_tec_OBCMgmt_AcChrgnSts_Enum: accessed-variable=RTE_R_OBCMgmt_AcChrgnSts_Enum.tec_OBCMgmt_AcChrgnSts_Enum
            REC_RTE_R_OBCMgmt_CPStsJmpErr_Bus_tec_OBCMgmt_CPStsJmpErr_Bus: accessed-variable=RTE_R_OBCMgmt_CPStsJmpErr_Bus.tec_OBCMgmt_CPStsJmpErr_Bus
            REC_RTE_R_OBCMgmt_OBCChrgStsErr_Bus_tec_OBCMgmt_OBCChrgStsErr_Bus: accessed-variable=RTE_R_OBCMgmt_OBCChrgStsErr_Bus.tec_OBCMgmt_OBCChrgStsErr_Bus
            REC_RTE_R_OBCMgmt_OBCDchaStsErr_Bus_tec_OBCMgmt_OBCDchaStsErr_Bus: accessed-variable=RTE_R_OBCMgmt_OBCDchaStsErr_Bus.tec_OBCMgmt_OBCDchaStsErr_Bus
            REC_RTE_R_OBCMgmt_OBCDiErr_Bus_tec_OBCMgmt_OBCDiErr_Bus: accessed-variable=RTE_R_OBCMgmt_OBCDiErr_Bus.tec_OBCMgmt_OBCDiErr_Bus
            REC_RTE_R_OBCMgmt_OBCInpUDcLoErr_Bus_tec_OBCMgmt_OBCInpUDcLoErr_Bus: accessed-variable=RTE_R_OBCMgmt_OBCInpUDcLoErr_Bus.tec_OBCMgmt_OBCInpUDcLoErr_Bus
            REC_RTE_R_OBCMgmt_OBCPreheatStsErr_Bus_tec_OBCMgmt_OBCPreheatStsErr_Bus: accessed-variable=RTE_R_OBCMgmt_OBCPreheatStsErr_Bus.tec_OBCMgmt_OBCPreheatStsErr_Bus
            REC_RTE_R_OBCMgmt_S2SwtClsErr_Bus_tec_OBCMgmt_S2SwtClsErr_Bus: accessed-variable=RTE_R_OBCMgmt_S2SwtClsErr_Bus.tec_OBCMgmt_S2SwtClsErr_Bus
            REC_RTE_R_VehMot_VehStdl_Flg_tec_VehMot_VehStdl_Flg: accessed-variable=RTE_R_VehMot_VehStdl_Flg.tec_VehMot_VehStdl_Flg
            REC_RTE_RP_ChrgStatInfo_tec_ChrgStatInfo: accessed-variable=RTE_RP_ChrgStatInfo.tec_ChrgStatInfo
            REC_UDS_PwrCutRequest_PwrCutRequest: accessed-variable=UDS_PwrCutRequest.PwrCutRequest
            REC_RTE_R_DiagApp_DisableDCMReqInfo_tec_DiagApp_DisableDCMReqInfo: accessed-variable=RTE_R_DiagApp_DisableDCMReqInfo.tec_DiagApp_DisableDCMReqInfo
            REC_RTE_R_ComM_OBCCPPwmDuty_pct_tec_ComM_OBCCPPwmDuty_pct: accessed-variable=RTE_R_ComM_OBCCPPwmDuty_pct.tec_ComM_OBCCPPwmDuty_pct
            REC_RTE_R_ComM_RxSts_Flg_tec_ComM_RxCSTSts_Flg: accessed-variable=RTE_R_ComM_RxSts_Flg.tec_ComM_RxCSTSts_Flg
            REC_RTE_R_HvMgmt_BMSNegRlyActSts_Enum_tec_HvMgmt_BMSNegRlyActSts_Enum: accessed-variable=RTE_R_HvMgmt_BMSNegRlyActSts_Enum.tec_HvMgmt_BMSNegRlyActSts_Enum
            REC_RTE_R_ComM_SGWDchaSwtSts_tec_ComM_SGWDchaSwtSts: accessed-variable=RTE_R_ComM_SGWDchaSwtSts.tec_ComM_SGWDchaSwtSts
            REC_RTE_R_DCChrMgmt_BSTTxReqSts_tec_DCChrMgmt_BSTTxReqSts: accessed-variable=RTE_R_DCChrMgmt_BSTTxReqSts.tec_DCChrMgmt_BSTTxReqSts
            REC_RTE_R_OBCMgmt_OBCEnaCmd_Enum_tec_OBCMgmt_OBCEnaCmd_Enum: accessed-variable=RTE_R_OBCMgmt_OBCEnaCmd_Enum.tec_OBCMgmt_OBCEnaCmd_Enum
            REC_RTE_R_VehMot_VehSpdVld_Flg_tec_VehMot_VehSpdVld_Flg: accessed-variable=RTE_R_VehMot_VehSpdVld_Flg.tec_VehMot_VehSpdVld_Flg
        data-send-points:
          20 x access:
            SEND_RTE_P_ChgMrmt_DchaAbortRsn_Enum_tec_ChrMgmt_DchaAbortRsn_Enum: accessed-variable=RTE_P_ChgMrmt_DchaAbortRsn_Enum.tec_ChrMgmt_DchaAbortRsn_Enum
            SEND_RTE_P_ChrMgmt_CC2UDcDTC_Bus_tec_ChrMgmt_CC2UDcErrDTC_Bus: accessed-variable=RTE_P_ChrMgmt_CC2UDcDTC_Bus.tec_ChrMgmt_CC2UDcErrDTC_Bus
            SEND_RTE_P_ChrMgmt_CC2UDcErr_Bus_tec_ChrMgmt_CC2UDcErr_Bus: accessed-variable=RTE_P_ChrMgmt_CC2UDcErr_Bus.tec_ChrMgmt_CC2UDcErr_Bus
            SEND_RTE_P_ChrMgmt_ChrgAbortRsn_Enum_tec_ChrMgmt_ChrgAbortRsn_Enum: accessed-variable=RTE_P_ChrMgmt_ChrgAbortRsn_Enum.tec_ChrMgmt_ChrgAbortRsn_Enum
            SEND_RTE_P_ChrMgmt_ChrgMemFlt_Flg_tec_ChrMgmt_ChrgMemFlt_Flg: accessed-variable=RTE_P_ChrMgmt_ChrgMemFlt_Flg.tec_ChrMgmt_ChrgMemFlt_Flg
            SEND_RTE_P_ChrMgmt_ChrgProcCmt_Enum_tec_ChrMgmt_ChrgProcCmt_Enum: accessed-variable=RTE_P_ChrMgmt_ChrgProcCmt_Enum.tec_ChrMgmt_ChrgProcCmt_Enum
            SEND_RTE_P_ChrMgmt_ChrgStsJmpDTC_Bus_tec_ChrMgmt_ChrgStsJmpErrDTC_Bus: accessed-variable=RTE_P_ChrMgmt_ChrgStsJmpDTC_Bus.tec_ChrMgmt_ChrgStsJmpErrDTC_Bus
            SEND_RTE_P_ChrMgmt_ChrgStsJmpErr_Bus_tec_ChrMgmt_ChrgStsJmpErr_Bus: accessed-variable=RTE_P_ChrMgmt_ChrgStsJmpErr_Bus.tec_ChrMgmt_ChrgStsJmpErr_Bus
            SEND_RTE_P_ChrMgmt_ChrgSts_Enum_tec_ChrMgmt_ChrgSts_Enum: accessed-variable=RTE_P_ChrMgmt_ChrgSts_Enum.tec_ChrMgmt_ChrgSts_Enum
            SEND_RTE_P_ChrMgmt_ChrgTarSOC_pct_tec_ChrMgmt_ChrgTarSOC_pct: accessed-variable=RTE_P_ChrMgmt_ChrgTarSOC_pct.tec_ChrMgmt_ChrgTarSOC_pct
            SEND_RTE_P_ChrMgmt_DcChrgAllwd_Flg_tec_ChrMgmt_DcChrgAllwd_Flg: accessed-variable=RTE_P_ChrMgmt_DcChrgAllwd_Flg.tec_ChrMgmt_DcChrgAllwd_Flg
            SEND_RTE_P_ChrMgmt_DcChrgCmplSts_Enum_tec_ChrMgmt_DcChrgCmplSts_Enum: accessed-variable=RTE_P_ChrMgmt_DcChrgCmplSts_Enum.tec_ChrMgmt_DcChrgCmplSts_Enum
            SEND_RTE_P_ChrMgmt_DchaAbortSOC_pct_tec_ChrMgmt_DchaAbortSOC_pct: accessed-variable=RTE_P_ChrMgmt_DchaAbortSOC_pct.tec_ChrMgmt_DchaAbortSOC_pct
            SEND_RTE_P_ChrMgmt_KeepWrm_Flg_tec_ChrMgmt_KeepWrm_Flg: accessed-variable=RTE_P_ChrMgmt_KeepWrm_Flg.tec_ChrMgmt_KeepWrm_Flg
            SEND_RTE_P_ChrMgmt_OBCCtrlMdlSts_Enum_tec_ChrMgmt_OBCCtrlMdlSts_Enum: accessed-variable=RTE_P_ChrMgmt_OBCCtrlMdlSts_Enum.tec_ChrMgmt_OBCCtrlMdlSts_Enum
            SEND_RTE_P_ChrMgmt_OBCEnaAllwd_Flg_tec_ChrMgmt_OBCEnaAllwd_Flg: accessed-variable=RTE_P_ChrMgmt_OBCEnaAllwd_Flg.tec_ChrMgmt_OBCEnaAllwd_Flg
            SEND_RTE_P_ChrMgmt_PlugSts_Enum_tec_ChrMgmt_PlugSts_Enum: accessed-variable=RTE_P_ChrMgmt_PlugSts_Enum.tec_ChrMgmt_PlugSts_Enum
            SEND_RTE_P_ChrMgmt_ReqHvRdy_Flg_tec_ChrMgmt_ReqHvRdy_Flg: accessed-variable=RTE_P_ChrMgmt_ReqHvRdy_Flg.tec_ChrMgmt_ReqHvRdy_Flg
            SEND_RTE_P_ChrMgmt_ReqLvActv_Flg_tec_ChrMgmt_ReqLvActv_Flg: accessed-variable=RTE_P_ChrMgmt_ReqLvActv_Flg.tec_ChrMgmt_ReqLvActv_Flg
            SEND_RTE_RP_ChrgStatInfo_tec_ChrgStatInfo: accessed-variable=RTE_RP_ChrgStatInfo.tec_ChrgStatInfo
      runnable R_ChrgStat_Init
  swc implementation CtAp_ChrgStat_Implementation: behavior=CtAp_ChrgStat_InternalBehavior
